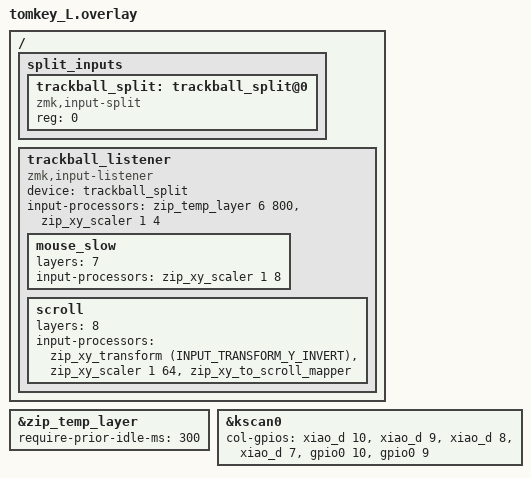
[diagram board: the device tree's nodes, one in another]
#include "tomkey.dtsi"
#include <dt-bindings/zmk/input_transform.h>
#include <input/processors.dtsi>
#include <zephyr/dt-bindings/input/input-event-codes.h>

/ {
    split_inputs {
        #address-cells = <1>;
        #size-cells = <0>;

        trackball_split: trackball_split@0 {
            compatible = "zmk,input-split";
            reg = <0>;
        };
    };

    trackball_listener: trackball_listener {
        compatible = "zmk,input-listener";
        status = "disabled";
        device = <&trackball_split>;
    };
};

/*
 * Do not enter the auto mouse layer within 300 ms of a key press, so that
 * bumping the trackball while typing does not switch layers. The cursor
 * still moves, and an already active mouse layer is not affected.
 */
&zip_temp_layer {
    require-prior-idle-ms = <300>;
};

/*
 * Scales are tuned for the sensor's cpi of 1600 in tomkey_R.overlay.
 * Older driver builds failed to apply that cpi, so these were lowered
 * after the fixed driver made the trackball faster.
 * Effective counts per inch: normal 400, slow 200, scroll 25.
 * The 800 in zip_temp_layer is the mouse layer timeout in ms, not speed.
 */
&trackball_listener {
    status = "okay";
    input-processors = <&zip_temp_layer 6 800>, <&zip_xy_scaler 1 4>;

    mouse_slow {
        layers = <7>;
        input-processors = <&zip_xy_scaler 1 8>;
    };

    scroll {
        layers = <8>;
        input-processors = <&zip_xy_transform (INPUT_TRANSFORM_Y_INVERT)>, <&zip_xy_scaler 1 64>, <&zip_xy_to_scroll_mapper>;
    };
};


&kscan0 {
        col-gpios
            = <&xiao_d 10 GPIO_ACTIVE_HIGH>
            , <&xiao_d 9 GPIO_ACTIVE_HIGH>
            , <&xiao_d 8 GPIO_ACTIVE_HIGH>
            , <&xiao_d 7 GPIO_ACTIVE_HIGH>
            , <&gpio0 10 GPIO_ACTIVE_HIGH>
            , <&gpio0 9 GPIO_ACTIVE_HIGH>
            ;
};
